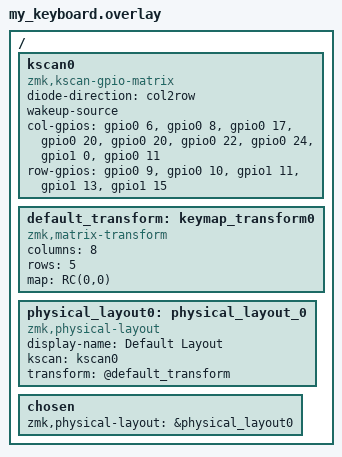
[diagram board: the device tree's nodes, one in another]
#include <dt-bindings/zmk/matrix_transform.h> // Put this with the other includes at the top of your overlay

/ {
    kscan0: kscan0 {
        compatible = "zmk,kscan-gpio-matrix";
        diode-direction = "col2row";//actually no diodes!
        wakeup-source;

        col-gpios
            = <&gpio0 6 GPIO_ACTIVE_HIGH>
            , <&gpio0 8 GPIO_ACTIVE_HIGH>
            , <&gpio0 17 GPIO_ACTIVE_HIGH>
            , <&gpio0 20 GPIO_ACTIVE_HIGH>
            , <&gpio0 20 GPIO_ACTIVE_HIGH>
            < &gpio0 22 GPIO_ACTIVE_HIGH>
            < &gpio0 24 GPIO_ACTIVE_HIGH>
            < &gpio1 0 GPIO_ACTIVE_HIGH>
            < &gpio0 11 GPIO_ACTIVE_HIGH>
            ;

        row-gpios
            = <&gpio0 9 (GPIO_ACTIVE_HIGH | GPIO_PULL_DOWN)>
            , <&gpio0 10 (GPIO_ACTIVE_HIGH | GPIO_PULL_DOWN)>
            , <&gpio1 11 (GPIO_ACTIVE_HIGH | GPIO_PULL_DOWN)>
            , <&gpio1 13 (GPIO_ACTIVE_HIGH | GPIO_PULL_DOWN)>
            , <&gpio1 15 (GPIO_ACTIVE_HIGH | GPIO_PULL_DOWN)>
            ;
    };
};

/ {
    default_transform: keymap_transform0 {
        compatible = "zmk,matrix-transform";
        columns = <8>; // Length of the "col-gpios" array
        rows = <5>; // Length of the "row-gpios" array
        map = <
            RC(0,0)
        >;
    };
};

/ {
    physical_layout0: physical_layout_0 {
        compatible = "zmk,physical-layout";
        display-name = "Default Layout";
        kscan = <&kscan0>;
        transform = <@default_transform>;
    };
};

/ {
    chosen {
        zmk,physical-layout = &physical_layout0;
    };
};
